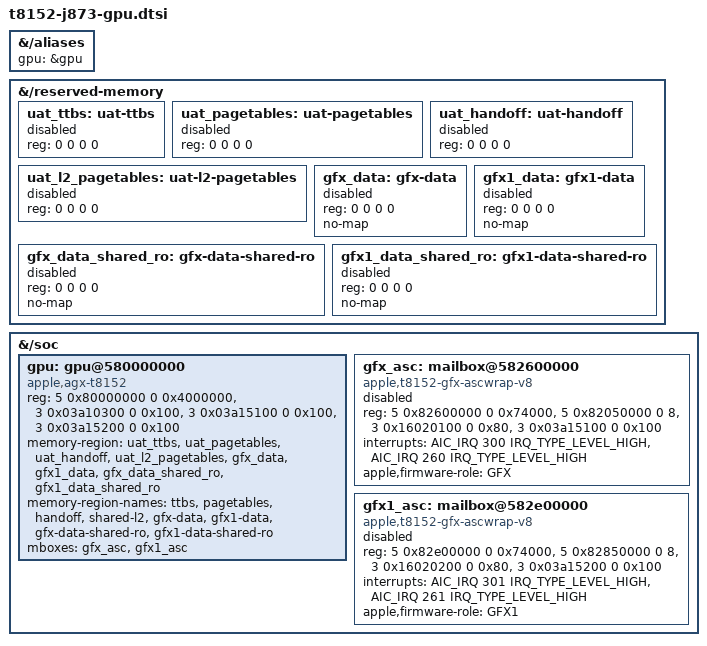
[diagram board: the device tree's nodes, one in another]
// SPDX-License-Identifier: GPL-2.0+ OR MIT
/*
 * J873 (Mac mini M6, T8152) G18G GPU resources, from the live 26A428 ADT
 * (full38-live-adt.bin). This is plumbing only: it qualifies no firmware,
 * power sequence or rendering.
 *
 * Gating, by default:
 *  - the asahi driver binds "apple,agx-t8152" but refuses with ENODEV and
 *    performs no MMIO while asahi.g18_initdata_test=0 (the default);
 *  - the eight reserved regions are boot-local and stay disabled with a zero
 *    reg until the loader copies this boot's /arm-io/sgx base and size
 *    values into them and sets status = "okay" (m1n1 dt_set_resvmem()
 *    pattern);
 *  - the four firmware segment carveouts (GFX/GFX1 __DATA and
 *    __DATA_SHARED_RO) are "no-map": they sit below Linux RAM in an
 *    isolated firmware region, and a loader that adds reserved regions to
 *    the /memory map (m1n1 dt_set_memory()) skips no-map nodes, so they
 *    never enter the cacheable linear map. The driver only takes their
 *    resources and memremap()s __DATA read-only for crashlog scans. The
 *    four UAT nodes stay mapped: the driver borrows their pages as System
 *    RAM (Page::borrow_phys), exactly as on M5;
 *  - the two GFX/GFX1 ASCWrap v8 providers stay disabled. The loader
 *    (installer-prep-26A428/j873-linux-boot.py) sets status = "okay" on
 *    both, next to the /chosen aurora,g18g-gpu-firmware-profile receipt,
 *    only when both loaded TEXT images qualify; nothing else enables them.
 *    Even when enabled they only map their windows; ASC CPU control is
 *    refused unless the separate apple_mailbox.ascwrap_v8_cpu_control
 *    parameter is set (requires user approval), and the receive side is
 *    polled (no interrupt is enabled) unless apple_mailbox.ascwrap_v8_rx_irq
 *    is set (requires user approval).
 *
 * No PMGR power-domain is attached: J873 GPU power is PMGR2 PSD services
 * 3 (sgx), 81 (gfx-asc) and 82 (gfx1-asc). Their 0x100-byte service blocks
 * are listed for read-only state checks (state +0x80, ack +0xbc); no driver
 * in this tree writes their request register by default.
 */

/* Loaders locate the node through this alias (m1n1 dt_set_gpu()). */
&{/aliases} {
	gpu = &gpu;
};

&{/reserved-memory} {
	/* sgx gpu-region */
	uat_ttbs: uat-ttbs { reg = <0 0 0 0>; status = "disabled"; };
	/* sgx gfx-shared-region (0x80000) */
	uat_pagetables: uat-pagetables { reg = <0 0 0 0>; status = "disabled"; };
	/* sgx gfx-handoff */
	uat_handoff: uat-handoff { reg = <0 0 0 0>; status = "disabled"; };
	/* sgx gfx-shared-l2-region */
	uat_l2_pagetables: uat-l2-pagetables { reg = <0 0 0 0>; status = "disabled"; };
	/* GFX __DATA (0xbc000 on 26A428) */
	gfx_data: gfx-data { reg = <0 0 0 0>; no-map; status = "disabled"; };
	/* GFX1 __DATA (0xb4000 on 26A428) */
	gfx1_data: gfx1-data { reg = <0 0 0 0>; no-map; status = "disabled"; };
	/* GFX __DATA_SHARED_RO (0x8000, firmware VA +0x10c000); never host-writable */
	gfx_data_shared_ro: gfx-data-shared-ro { reg = <0 0 0 0>; no-map; status = "disabled"; };
	/* GFX1 __DATA_SHARED_RO (0x8000, firmware VA +0x108000); never host-writable */
	gfx1_data_shared_ro: gfx1-data-shared-ro { reg = <0 0 0 0>; no-map; status = "disabled"; };
};

&{/soc} {
	gpu: gpu@580000000 {
		compatible = "apple,agx-t8152";
		/*
		 * ADT sgx reg[0]. ADT reg[1] (0x580d00000/0x180000) lies inside
		 * it and is reached through this window. PSD blocks follow.
		 */
		reg = <5 0x80000000 0 0x4000000>,
		      <3 0x03a10300 0 0x100>,
		      <3 0x03a15100 0 0x100>,
		      <3 0x03a15200 0 0x100>;
		reg-names = "sgx", "psd-sgx", "psd-gfx-asc", "psd-gfx1-asc";
		memory-region = <&uat_ttbs>, <&uat_pagetables>, <&uat_handoff>,
				<&uat_l2_pagetables>, <&gfx_data>, <&gfx1_data>,
				<&gfx_data_shared_ro>, <&gfx1_data_shared_ro>;
		memory-region-names = "ttbs", "pagetables", "handoff", "shared-l2",
				      "gfx-data", "gfx1-data",
				      "gfx-data-shared-ro", "gfx1-data-shared-ro";
		mboxes = <&gfx_asc>, <&gfx1_asc>;
	};

	/*
	 * ADT gfx-asc: iop,ascwrap-v8, msgbox-mailbox-num=1, alias, postoffice.
	 * Only this role's 0x80-byte post-office window (0x316020000 +
	 * (2 * 1 + 0) * 0x80) is claimed; the rest of the 0x316020000 bank
	 * belongs to PMP/DCP/DCPEXT/SCALER0. ADT interrupts = <300 260>.
	 * Index 0 is send-empty and index 1 recv-not-empty: 26A428
	 * AppleASCWrapV8::_inboxEmptyInterruptIndex() returns 0 and
	 * _outboxNotEmptyInterruptIndex() returns 1 (KEXT_PROVEN), matching
	 * the SMC, whose index-1 line follows RX occupancy on hardware. Not yet
	 * observed for GFX; the provider polls by default.
	 */
	gfx_asc: mailbox@582600000 {
		compatible = "apple,t8152-gfx-ascwrap-v8";
		reg = <5 0x82600000 0 0x74000>, <5 0x82050000 0 8>,
		      <3 0x16020100 0 0x80>, <3 0x03a15100 0 0x100>;
		reg-names = "wrapper", "iop-vbar", "mailbox", "psd";
		interrupts = <AIC_IRQ 300 IRQ_TYPE_LEVEL_HIGH>,
			     <AIC_IRQ 260 IRQ_TYPE_LEVEL_HIGH>;
		interrupt-names = "send-empty", "recv-not-empty";
		apple,firmware-role = "GFX";
		#mbox-cells = <0>;
		status = "disabled";
	};

	/* ADT gfx1-asc: msgbox-mailbox-num=2, window 0x316020200. */
	gfx1_asc: mailbox@582e00000 {
		compatible = "apple,t8152-gfx-ascwrap-v8";
		reg = <5 0x82e00000 0 0x74000>, <5 0x82850000 0 8>,
		      <3 0x16020200 0 0x80>, <3 0x03a15200 0 0x100>;
		reg-names = "wrapper", "iop-vbar", "mailbox", "psd";
		interrupts = <AIC_IRQ 301 IRQ_TYPE_LEVEL_HIGH>,
			     <AIC_IRQ 261 IRQ_TYPE_LEVEL_HIGH>;
		interrupt-names = "send-empty", "recv-not-empty";
		apple,firmware-role = "GFX1";
		#mbox-cells = <0>;
		status = "disabled";
	};
};
